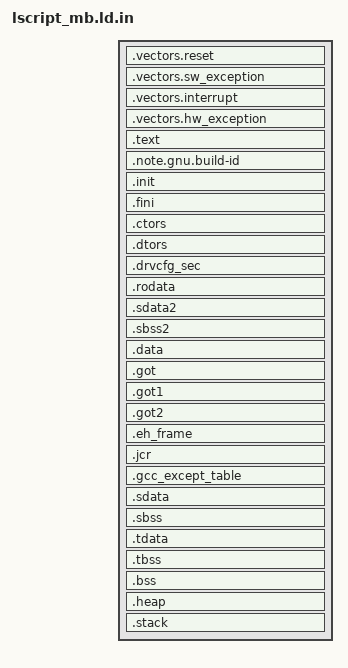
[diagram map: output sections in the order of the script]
/******************************************************************************
* Copyright (C) 2023 - 2025 Advanced Micro Devices, Inc. All Rights Reserved.
* SPDX-License-Identifier: MIT
******************************************************************************/

_STACK_SIZE = DEFINED(_STACK_SIZE) ? _STACK_SIZE : @STACK_SIZE@;
_HEAP_SIZE = DEFINED(_HEAP_SIZE) ? _HEAP_SIZE : @HEAP_SIZE@;

@MEMORY_SECTION@

/* Specify the default entry point to the program */

ENTRY(_start)

/* Define the sections, and where they are mapped in memory */

SECTIONS
{
.vectors.reset @V_RESET@ : {
   KEEP (*(.vectors.reset))
}

.vectors.sw_exception @V_EXCEPTION@ : {
   KEEP (*(.vectors.sw_exception))
}

.vectors.interrupt @V_INTERRUPT@ : {
   KEEP (*(.vectors.interrupt))
}

.vectors.hw_exception @V_HWEXCEPTION@ : {
   KEEP (*(.vectors.hw_exception))
}

.text : {
   *(.text)
   *(.text.*)
   *(.gnu.linkonce.t.*)
   *(.note.gnu.build-id)
} > @CODE@

.note.gnu.build-id : {
   KEEP (*(.note.gnu.build-id))
} > @CODE@

.init : {
   KEEP (*(.init))
} > @DATA@

.fini : {
   KEEP (*(.fini))
} > @DATA@

.ctors : {
   __CTOR_LIST__ = .;
   ___CTORS_LIST___ = .;
   KEEP (*crtbegin.o(.ctors))
   KEEP (*(EXCLUDE_FILE(*crtend.o) .ctors))
   KEEP (*(SORT(.ctors.*)))
   KEEP (*(.ctors))
   __CTOR_END__ = .;
   ___CTORS_END___ = .;
} > @DATA@

.dtors : {
   __DTOR_LIST__ = .;
   ___DTORS_LIST___ = .;
   KEEP (*crtend.o(.dtors))
   KEEP (*(EXCLUDE_FILE(*crtbegin.o) .dtors))
   KEEP (*(SORT(.dtors.*)))
   KEEP (*(.dtors))
   PROVIDE(__DTOR_END__ = .);
   PROVIDE(___DTORS_END___ = .);
} > @DATA@

.drvcfg_sec : {
    . = ALIGN(8);
     __drvcfgsecdata_start = .;
    KEEP (*(.drvcfg_sec))
    __drvcfgsecdata_end = .;
    __drvcfgsecdata_size = __drvcfgsecdata_end - __drvcfgsecdata_start;
} > @DATA@

.rodata : {
   __rodata_start = .;
   *(.rodata)
   *(.rodata.*)
   *(.gnu.linkonce.r.*)
   __rodata_end = .;
} > @DATA@

.sdata2 : {
   . = ALIGN(8);
   __sdata2_start = .;
   *(.sdata2)
   *(.sdata2.*)
   *(.gnu.linkonce.s2.*)
   . = ALIGN(8);
   __sdata2_end = .;
} > @DATA@

.sbss2 : {
   __sbss2_start = .;
   *(.sbss2)
   *(.sbss2.*)
   *(.gnu.linkonce.sb2.*)
   __sbss2_end = .;
} > @DATA@

.data : {
   . = ALIGN(4);
   __data_start = .;
   *(.data)
   *(.data.*)
   *(.gnu.linkonce.d.*)
   __data_end = .;
} > @DATA@

.got : {
   *(.got)
} > @DATA@

.got1 : {
   *(.got1)
} > @DATA@

.got2 : {
   *(.got2)
} > @DATA@

.eh_frame : {
   *(.eh_frame)
} > @DATA@

.jcr : {
   *(.jcr)
} > @DATA@

.gcc_except_table : {
   *(.gcc_except_table)
} > @DATA@

.sdata : {
   . = ALIGN(8);
   __sdata_start = .;
   *(.sdata)
   *(.sdata.*)
   *(.gnu.linkonce.s.*)
   __sdata_end = .;
} > @DATA@

.sbss (NOLOAD) : {
   . = ALIGN(4);
   __sbss_start = .;
   *(.sbss)
   *(.sbss.*)
   *(.gnu.linkonce.sb.*)
   . = ALIGN(8);
   __sbss_end = .;
} > @DATA@

.tdata : {
   __tdata_start = .;
   *(.tdata)
   *(.tdata.*)
   *(.gnu.linkonce.td.*)
   __tdata_end = .;
} > @DATA@

.tbss : {
   __tbss_start = .;
   *(.tbss)
   *(.tbss.*)
   *(.gnu.linkonce.tb.*)
   __tbss_end = .;
} > @DATA@

.bss (NOLOAD) : {
   . = ALIGN(4);
   __bss_start = .;
   *(.bss)
   *(.bss.*)
   *(.gnu.linkonce.b.*)
   *(COMMON)
   . = ALIGN(4);
   __bss_end = .;
} > @DATA@

_SDA_BASE_ = __sdata_start + ((__sbss_end - __sdata_start) / 2 );

_SDA2_BASE_ = __sdata2_start + ((__sbss2_end - __sdata2_start) / 2 );

/* Generate Stack and Heap definitions */

.heap (NOLOAD) : {
   . = ALIGN(8);
   _heap = .;
   _heap_start = .;
   . += _HEAP_SIZE;
   _heap_end = .;
} > @DATA@

.stack (NOLOAD) : {
   _stack_end = .;
   . += _STACK_SIZE;
   . = ALIGN(8);
   _stack = .;
   __stack = _stack;
} > @DATA@

_end = .;
}
